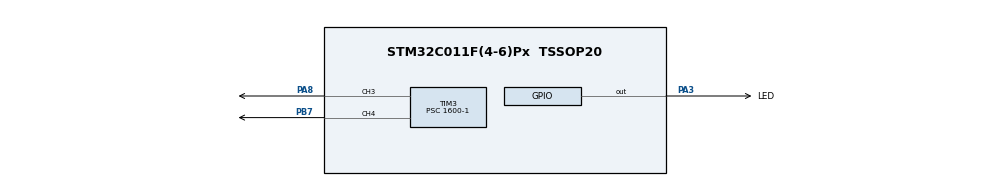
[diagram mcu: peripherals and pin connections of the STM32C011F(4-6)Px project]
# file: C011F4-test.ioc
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Dma.Request0=TIM3_CH3
Dma.Request1=TIM3_CH4
Dma.TIM3_CH3.0.Direction=DMA_MEMORY_TO_PERIPH
Dma.TIM3_CH3.0.EventEnable=DISABLE
Dma.TIM3_CH3.0.Instance=DMA1_Channel1
Dma.TIM3_CH3.0.MemDataAlignment=DMA_MDATAALIGN_HALFWORD
Dma.TIM3_CH3.0.MemInc=DMA_MINC_ENABLE
Dma.TIM3_CH3.0.Mode=DMA_CIRCULAR
Dma.TIM3_CH3.0.PeriphDataAlignment=DMA_PDATAALIGN_HALFWORD
Dma.TIM3_CH3.0.PeriphInc=DMA_PINC_DISABLE
Dma.TIM3_CH3.0.Polarity=HAL_DMAMUX_REQ_GEN_RISING
Dma.TIM3_CH3.0.Priority=DMA_PRIORITY_LOW
Dma.TIM3_CH3.0.RequestNumber=1
Dma.TIM3_CH3.0.SignalID=NONE
Dma.TIM3_CH3.0.SyncEnable=DISABLE
Dma.TIM3_CH3.0.SyncPolarity=HAL_DMAMUX_SYNC_NO_EVENT
Dma.TIM3_CH3.0.SyncRequestNumber=1
Dma.TIM3_CH3.0.SyncSignalID=NONE
Dma.TIM3_CH4.1.Direction=DMA_MEMORY_TO_PERIPH
Dma.TIM3_CH4.1.EventEnable=DISABLE
Dma.TIM3_CH4.1.Instance=DMA1_Channel2
Dma.TIM3_CH4.1.MemDataAlignment=DMA_MDATAALIGN_HALFWORD
Dma.TIM3_CH4.1.MemInc=DMA_MINC_ENABLE
Dma.TIM3_CH4.1.Mode=DMA_CIRCULAR
Dma.TIM3_CH4.1.PeriphDataAlignment=DMA_PDATAALIGN_HALFWORD
Dma.TIM3_CH4.1.PeriphInc=DMA_PINC_DISABLE
Dma.TIM3_CH4.1.Polarity=HAL_DMAMUX_REQ_GEN_RISING
Dma.TIM3_CH4.1.Priority=DMA_PRIORITY_LOW
Dma.TIM3_CH4.1.RequestNumber=1
Dma.TIM3_CH4.1.SignalID=NONE
Dma.TIM3_CH4.1.SyncEnable=DISABLE
Dma.TIM3_CH4.1.SyncPolarity=HAL_DMAMUX_SYNC_NO_EVENT
Dma.TIM3_CH4.1.SyncRequestNumber=1
Dma.TIM3_CH4.1.SyncSignalID=NONE
Mcu.Family=STM32C0
Mcu.Name=STM32C011F(4-6)Px
Mcu.Package=TSSOP20
NVIC.DMA1_Channel1_IRQn=true\:0\:0\:false\:false\:true\:false\:true\:true
NVIC.DMA1_Channel2_3_IRQn=true\:0\:0\:false\:false\:true\:false\:true\:true
PA13.Mode=Serial_Wire
PA13.Signal=DEBUG_SWDIO
PA14-BOOT0.Mode=Serial_Wire
PA14-BOOT0.Signal=DEBUG_SWCLK
PA3.GPIO_Label=LED
PA3.Signal=GPIO_Output
PA8.Signal=S_TIM3_CH3
PB7.Signal=S_TIM3_CH4
PC14-OSCX_IN\ (PC14).Mode=HSE-External-Oscillator-REMAPPED
PC14-OSCX_IN\ (PC14).Signal=RCC_OSCX_IN
PC15-OSCX_OUT\ (PC15).Mode=HSE-External-Oscillator-REMAPPED
PC15-OSCX_OUT\ (PC15).Signal=RCC_OSCX_OUT
ProjectManager.HeapSize=0x200
ProjectManager.StackSize=0x400
ProjectManager.TargetToolchain=STM32CubeIDE
RCC.ADCFreq_Value=32000000
RCC.AHBFreq_Value=32000000
RCC.CortexFreq_Value=32000000
RCC.EXTERNAL_CLOCK_VALUE=12288000
RCC.HCLKFreq_Value=32000000
RCC.HSE_VALUE=32000000
RCC.HSISYSCLKDivider=RCC_HSI_DIV2
RCC.HSI_VALUE=48000000
RCC.LSE_VALUE=32768
RCC.SYSCLKFreq_VALUE=32000000
RCC.SYSCLKSource=RCC_SYSCLKSOURCE_HSE
SH.S_TIM3_CH3.0=TIM3_CH3,PWM Generation3 CH3
SH.S_TIM3_CH4.0=TIM3_CH4,PWM Generation4 CH4
TIM3.AutoReloadPreload=TIM_AUTORELOAD_PRELOAD_ENABLE
TIM3.Channel-PWM\ Generation3\ CH3=TIM_CHANNEL_3
TIM3.Channel-PWM\ Generation4\ CH4=TIM_CHANNEL_4
TIM3.OC3Preload_PWM=ENABLE
TIM3.OCFastMode_PWM-PWM\ Generation3\ CH3=TIM_OCFAST_DISABLE
TIM3.Period=1000-1
TIM3.Prescaler=1600-1
VP_TIM3_VS_ClockSourceINT.Mode=Internal
board=custom

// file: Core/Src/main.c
/* USER CODE BEGIN Header */
/**
  ******************************************************************************
  * @file           : main.c
  * @brief          : Main program body
  ******************************************************************************
  * @attention
  *
  * Copyright (c) 2024 STMicroelectronics.
  * All rights reserved.
  *
  * This software is licensed under terms that can be found in the LICENSE file
  * in the root directory of this software component.
  * If no LICENSE file comes with this software, it is provided AS-IS.
  *
  ******************************************************************************
  */
/* USER CODE END Header */
#include "main.h"

TIM_HandleTypeDef htim3;
DMA_HandleTypeDef hdma_tim3_ch3;
DMA_HandleTypeDef hdma_tim3_ch4;

void SystemClock_Config(void);
static void MX_GPIO_Init(void);
static void MX_DMA_Init(void);
static void MX_TIM3_Init(void);

/* USER CODE BEGIN 0 */

uint16_t  pwmlist1[] = {
  100, 200, 300, 400, 500
};
uint16_t  pwmlist2[] = {
  900, 800, 700, 600, 500
};

/* USER CODE END 0 */

int main(void)
{

  /* MCU Configuration--------------------------------------------------------*/

  /* Reset of all peripherals, Initializes the Flash interface and the Systick. */
  HAL_Init();

  /* Configure the system clock */
  SystemClock_Config();

  /* Initialize all configured peripherals */
  MX_GPIO_Init();
  MX_DMA_Init();
  MX_TIM3_Init();
  /* USER CODE BEGIN 2 */
//  HAL_TIM_PWM_Start(&htim3, TIM_CHANNEL_3);
//  HAL_TIM_PWM_Start(&htim3, TIM_CHANNEL_4);
//  __HAL_TIM_SET_COMPARE(&htim3, TIM_CHANNEL_3, 500);
//  __HAL_TIM_SET_COMPARE(&htim3, TIM_CHANNEL_4, 500);

  HAL_TIM_PWM_Start_DMA (&htim3, TIM_CHANNEL_3, (uint32_t*)pwmlist1, sizeof (pwmlist1) / sizeof (uint16_t));
  htim3.State = HAL_TIM_STATE_READY;
  HAL_TIM_PWM_Start_DMA (&htim3, TIM_CHANNEL_4, (uint32_t*)pwmlist2, sizeof (pwmlist2) / sizeof (uint16_t));

  /* USER CODE END 2 */

  /* Infinite loop */
  while (1)
  {

    /* USER CODE BEGIN 3 */
	HAL_GPIO_WritePin(LED_GPIO_Port, LED_Pin,1);
	pwmlist1[0] = 100; pwmlist1[1] = 200; pwmlist1[2] = 300;
	pwmlist1[3] = 400; pwmlist1[4] = 500;
   	HAL_Delay(1000);
   	HAL_GPIO_WritePin(LED_GPIO_Port, LED_Pin,0);
	pwmlist1[0] = 900; pwmlist1[1] = 900; pwmlist1[2] = 900;
	pwmlist1[3] = 900; pwmlist1[4] = 900;
   	HAL_Delay(1000);
  }
  /* USER CODE END 3 */
}

void SystemClock_Config(void)
{
  RCC_OscInitTypeDef RCC_OscInitStruct = {0};
  RCC_ClkInitTypeDef RCC_ClkInitStruct = {0};

  /** Initializes the RCC Oscillators according to the specified parameters
  * in the RCC_OscInitTypeDef structure.
  */
  RCC_OscInitStruct.OscillatorType = RCC_OSCILLATORTYPE_HSE;
  RCC_OscInitStruct.HSEState = RCC_HSE_ON;
  if (HAL_RCC_OscConfig(&RCC_OscInitStruct) != HAL_OK)
  {
    Error_Handler();
  }

  /** Initializes the CPU, AHB and APB buses clocks
  */
  RCC_ClkInitStruct.ClockType = RCC_CLOCKTYPE_HCLK|RCC_CLOCKTYPE_SYSCLK
                              |RCC_CLOCKTYPE_PCLK1;
  RCC_ClkInitStruct.SYSCLKSource = RCC_SYSCLKSOURCE_HSE;
  RCC_ClkInitStruct.SYSCLKDivider = RCC_SYSCLK_DIV1;
  RCC_ClkInitStruct.AHBCLKDivider = RCC_HCLK_DIV1;
  RCC_ClkInitStruct.APB1CLKDivider = RCC_APB1_DIV1;

  if (HAL_RCC_ClockConfig(&RCC_ClkInitStruct, FLASH_LATENCY_1) != HAL_OK)
  {
    Error_Handler();
  }
}

static void MX_TIM3_Init(void)
{

  TIM_ClockConfigTypeDef sClockSourceConfig = {0};
  TIM_MasterConfigTypeDef sMasterConfig = {0};
  TIM_OC_InitTypeDef sConfigOC = {0};

  htim3.Instance = TIM3;
  htim3.Init.Prescaler = 1600-1;
  htim3.Init.CounterMode = TIM_COUNTERMODE_UP;
  htim3.Init.Period = 1000-1;
  htim3.Init.ClockDivision = TIM_CLOCKDIVISION_DIV1;
  htim3.Init.AutoReloadPreload = TIM_AUTORELOAD_PRELOAD_ENABLE;
  if (HAL_TIM_Base_Init(&htim3) != HAL_OK)
  {
    Error_Handler();
  }
  sClockSourceConfig.ClockSource = TIM_CLOCKSOURCE_INTERNAL;
  if (HAL_TIM_ConfigClockSource(&htim3, &sClockSourceConfig) != HAL_OK)
  {
    Error_Handler();
  }
  if (HAL_TIM_PWM_Init(&htim3) != HAL_OK)
  {
    Error_Handler();
  }
  sMasterConfig.MasterOutputTrigger = TIM_TRGO_RESET;
  sMasterConfig.MasterSlaveMode = TIM_MASTERSLAVEMODE_DISABLE;
  if (HAL_TIMEx_MasterConfigSynchronization(&htim3, &sMasterConfig) != HAL_OK)
  {
    Error_Handler();
  }
  sConfigOC.OCMode = TIM_OCMODE_PWM1;
  sConfigOC.Pulse = 0;
  sConfigOC.OCPolarity = TIM_OCPOLARITY_HIGH;
  sConfigOC.OCFastMode = TIM_OCFAST_DISABLE;
  if (HAL_TIM_PWM_ConfigChannel(&htim3, &sConfigOC, TIM_CHANNEL_3) != HAL_OK)
  {
    Error_Handler();
  }
  if (HAL_TIM_PWM_ConfigChannel(&htim3, &sConfigOC, TIM_CHANNEL_4) != HAL_OK)
  {
    Error_Handler();
  }
  HAL_TIM_MspPostInit(&htim3);

}

static void MX_DMA_Init(void)
{

  /* DMA controller clock enable */
  __HAL_RCC_DMA1_CLK_ENABLE();

  /* DMA interrupt init */
  /* DMA1_Channel1_IRQn interrupt configuration */
  HAL_NVIC_SetPriority(DMA1_Channel1_IRQn, 0, 0);
  HAL_NVIC_EnableIRQ(DMA1_Channel1_IRQn);
  /* DMA1_Channel2_3_IRQn interrupt configuration */
  HAL_NVIC_SetPriority(DMA1_Channel2_3_IRQn, 0, 0);
  HAL_NVIC_EnableIRQ(DMA1_Channel2_3_IRQn);

}

static void MX_GPIO_Init(void)
{
  GPIO_InitTypeDef GPIO_InitStruct = {0};

  /* GPIO Ports Clock Enable */
  __HAL_RCC_GPIOB_CLK_ENABLE();
  __HAL_RCC_GPIOC_CLK_ENABLE();
  __HAL_RCC_GPIOA_CLK_ENABLE();

  /*Configure GPIO pin Output Level */
  HAL_GPIO_WritePin(LED_GPIO_Port, LED_Pin, GPIO_PIN_RESET);

  /*Configure GPIO pin : LED_Pin */
  GPIO_InitStruct.Pin = LED_Pin;
  GPIO_InitStruct.Mode = GPIO_MODE_OUTPUT_PP;
  GPIO_InitStruct.Pull = GPIO_NOPULL;
  GPIO_InitStruct.Speed = GPIO_SPEED_FREQ_LOW;
  HAL_GPIO_Init(LED_GPIO_Port, &GPIO_InitStruct);

}

void Error_Handler(void)
{
  __disable_irq();
  while (1)
  {
  }
}
